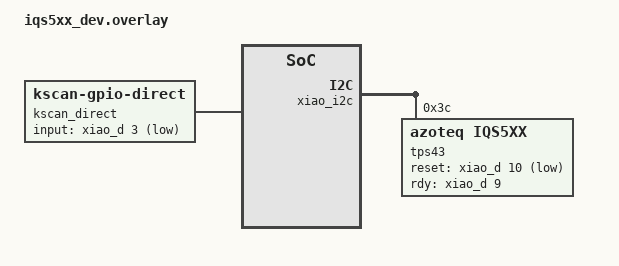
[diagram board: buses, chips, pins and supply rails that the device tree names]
#include <dt-bindings/zmk/matrix_transform.h>

/ {
	chosen {
		zmk,kscan = &kscan_direct;
		zmk,matrix-transform = &default_transform;
	};
    kscan_direct: kscan_direct {
        compatible = "zmk,kscan-gpio-direct";
        wakeup-source;

        input-gpios
        = <&xiao_d 3 (GPIO_ACTIVE_LOW | GPIO_PULL_UP)>;

    };

    default_transform: keymap_transform_0 {
        compatible = "zmk,matrix-transform";
        columns = <1>;
        rows = <1>;
        map = < RC(0,0) >;
    };

    tps43_input: tps43_input {
        compatible = "zmk,input-listener";
        device = <&tps43>;
    };
};

/*
* SDA: D4
* SCL: D5
* reg = <0x74>;
*/
&xiao_i2c {
    status = "okay";
    tps43: iqs5xx@3c {
        status = "okay";
        compatible = "azoteq,iqs5xx";
        
        reg = <0x3c>;

        one-finger-tap;
        press-and-hold;
        press-and-hold-time = <250>;
        two-finger-tap;

        scroll;
        natural-scroll-y;
        natural-scroll-x;

        bottom-beta = <5>;
        stationary-threshold = <5>;

        switch-xy;
        reset-gpios = <&xiao_d 10 GPIO_ACTIVE_LOW>; /* D2 */
        rdy-gpios = <&xiao_d 9 GPIO_ACTIVE_HIGH>; /* D3 */
    };
};
